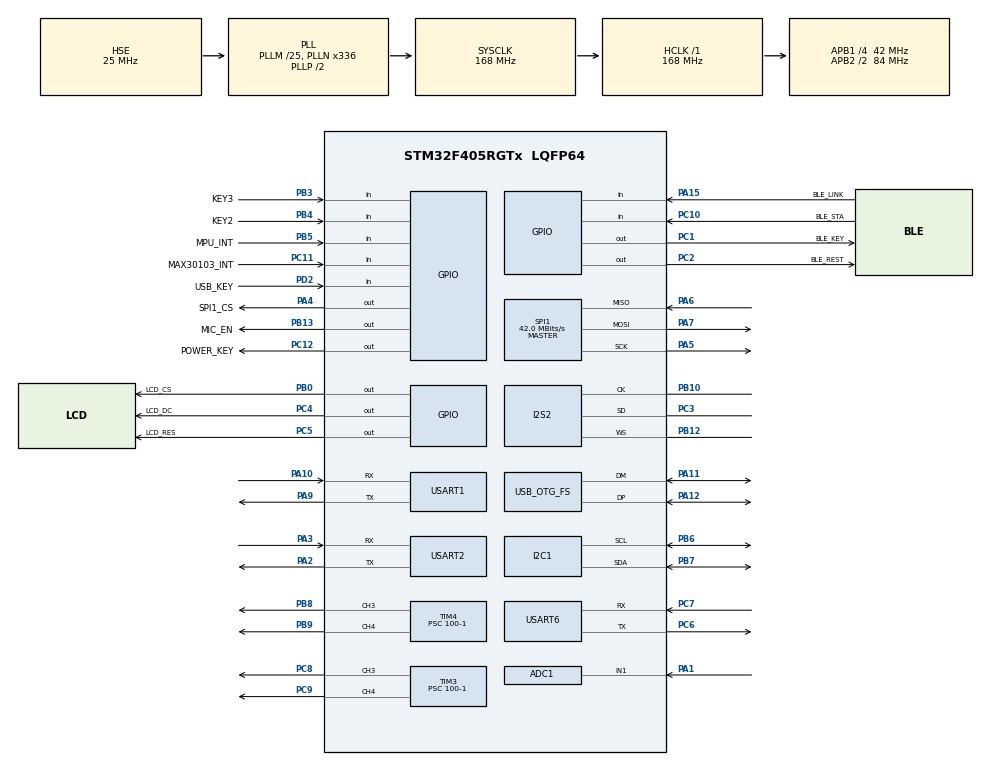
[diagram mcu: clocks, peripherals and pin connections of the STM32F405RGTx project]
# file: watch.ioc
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ADC1.Channel-0\#ChannelRegularConversion=ADC_CHANNEL_1
ADC1.NbrOfConversionFlag=1
ADC1.Rank-0\#ChannelRegularConversion=1
ADC1.SamplingTime-0\#ChannelRegularConversion=ADC_SAMPLETIME_3CYCLES
ADC1.master=1
Dma.Request0=SPI2_TX
Dma.Request1=USART2_TX
Dma.Request2=USART2_RX
Dma.Request3=SPI1_TX
Dma.Request4=USART1_RX
Dma.Request5=USART1_TX
Dma.SPI1_TX.3.Direction=DMA_MEMORY_TO_PERIPH
Dma.SPI1_TX.3.FIFOMode=DMA_FIFOMODE_DISABLE
Dma.SPI1_TX.3.Instance=DMA2_Stream3
Dma.SPI1_TX.3.MemDataAlignment=DMA_MDATAALIGN_BYTE
Dma.SPI1_TX.3.MemInc=DMA_MINC_ENABLE
Dma.SPI1_TX.3.Mode=DMA_NORMAL
Dma.SPI1_TX.3.PeriphDataAlignment=DMA_PDATAALIGN_BYTE
Dma.SPI1_TX.3.PeriphInc=DMA_PINC_DISABLE
Dma.SPI1_TX.3.Priority=DMA_PRIORITY_HIGH
Dma.SPI2_TX.0.Direction=DMA_MEMORY_TO_PERIPH
Dma.SPI2_TX.0.FIFOMode=DMA_FIFOMODE_DISABLE
Dma.SPI2_TX.0.Instance=DMA1_Stream4
Dma.SPI2_TX.0.MemDataAlignment=DMA_MDATAALIGN_BYTE
Dma.SPI2_TX.0.MemInc=DMA_MINC_ENABLE
Dma.SPI2_TX.0.Mode=DMA_NORMAL
Dma.SPI2_TX.0.PeriphDataAlignment=DMA_PDATAALIGN_BYTE
Dma.SPI2_TX.0.PeriphInc=DMA_PINC_DISABLE
Dma.SPI2_TX.0.Priority=DMA_PRIORITY_LOW
Dma.USART1_RX.4.Direction=DMA_PERIPH_TO_MEMORY
Dma.USART1_RX.4.FIFOMode=DMA_FIFOMODE_DISABLE
Dma.USART1_RX.4.Instance=DMA2_Stream2
Dma.USART1_RX.4.MemDataAlignment=DMA_MDATAALIGN_BYTE
Dma.USART1_RX.4.MemInc=DMA_MINC_ENABLE
Dma.USART1_RX.4.Mode=DMA_NORMAL
Dma.USART1_RX.4.PeriphDataAlignment=DMA_PDATAALIGN_BYTE
Dma.USART1_RX.4.PeriphInc=DMA_PINC_DISABLE
Dma.USART1_RX.4.Priority=DMA_PRIORITY_LOW
Dma.USART1_TX.5.Direction=DMA_MEMORY_TO_PERIPH
Dma.USART1_TX.5.FIFOMode=DMA_FIFOMODE_DISABLE
Dma.USART1_TX.5.Instance=DMA2_Stream7
Dma.USART1_TX.5.MemDataAlignment=DMA_MDATAALIGN_BYTE
Dma.USART1_TX.5.MemInc=DMA_MINC_ENABLE
Dma.USART1_TX.5.Mode=DMA_NORMAL
Dma.USART1_TX.5.PeriphDataAlignment=DMA_PDATAALIGN_BYTE
Dma.USART1_TX.5.PeriphInc=DMA_PINC_DISABLE
Dma.USART1_TX.5.Priority=DMA_PRIORITY_LOW
Dma.USART2_RX.2.Direction=DMA_PERIPH_TO_MEMORY
Dma.USART2_RX.2.FIFOMode=DMA_FIFOMODE_DISABLE
Dma.USART2_RX.2.Instance=DMA1_Stream5
Dma.USART2_RX.2.MemDataAlignment=DMA_MDATAALIGN_BYTE
Dma.USART2_RX.2.MemInc=DMA_MINC_ENABLE
Dma.USART2_RX.2.Mode=DMA_NORMAL
Dma.USART2_RX.2.PeriphDataAlignment=DMA_PDATAALIGN_BYTE
Dma.USART2_RX.2.PeriphInc=DMA_PINC_DISABLE
Dma.USART2_RX.2.Priority=DMA_PRIORITY_LOW
Dma.USART2_TX.1.Direction=DMA_MEMORY_TO_PERIPH
Dma.USART2_TX.1.FIFOMode=DMA_FIFOMODE_DISABLE
Dma.USART2_TX.1.Instance=DMA1_Stream6
Dma.USART2_TX.1.MemDataAlignment=DMA_MDATAALIGN_BYTE
Dma.USART2_TX.1.MemInc=DMA_MINC_ENABLE
Dma.USART2_TX.1.Mode=DMA_NORMAL
Dma.USART2_TX.1.PeriphDataAlignment=DMA_PDATAALIGN_BYTE
Dma.USART2_TX.1.PeriphInc=DMA_PINC_DISABLE
Dma.USART2_TX.1.Priority=DMA_PRIORITY_LOW
FATFS._CODE_PAGE=437
FATFS._MAX_SS=4096
FATFS._MIN_SS=4096
FATFS._USE_LFN=3
FREERTOS.Tasks01=main,0,1024,StartDefaultTask,Default,NULL,Dynamic,NULL,NULL;base,1,2048,StartTask02,Default,NULL,Dynamic,NULL,NULL;background,-1,128,StartTask03,Default,NULL,Dynamic,NULL,NULL
FREERTOS.configTOTAL_HEAP_SIZE=18432
I2S2.DataFormat=I2S_DATAFORMAT_24B
I2S2.ErrorAudioFreq=-0.36 %
I2S2.FullDuplexMode=I2S_FULLDUPLEXMODE_DISABLE
I2S2.Instance=SPI$Index
I2S2.RealAudioFreq=7.971 KHz
I2S2.VirtualMode=I2S_MODE_MASTER
Mcu.Family=STM32F4
Mcu.Name=STM32F405RGTx
Mcu.Package=LQFP64
NVIC.DMA1_Stream4_IRQn=true\:5\:0\:false\:false\:true\:true\:false\:true\:true
NVIC.DMA1_Stream5_IRQn=true\:5\:0\:false\:false\:true\:true\:false\:true\:true
NVIC.DMA1_Stream6_IRQn=true\:5\:0\:false\:false\:true\:true\:false\:true\:true
NVIC.DMA2_Stream2_IRQn=true\:5\:0\:false\:false\:true\:true\:false\:true\:true
NVIC.DMA2_Stream3_IRQn=true\:5\:0\:false\:false\:true\:true\:false\:true\:true
NVIC.DMA2_Stream7_IRQn=true\:5\:0\:false\:false\:true\:true\:false\:true\:true
NVIC.OTG_FS_IRQn=true\:5\:0\:false\:false\:true\:true\:false\:true\:true
NVIC.PriorityGroup=NVIC_PRIORITYGROUP_4
NVIC.TIM2_IRQn=true\:15\:0\:false\:false\:true\:false\:false\:true\:true
NVIC.TIM5_IRQn=true\:5\:0\:true\:false\:true\:true\:true\:true\:true
NVIC.TimeBase=TIM2_IRQn
NVIC.TimeBaseIP=TIM2
NVIC.USART1_IRQn=true\:5\:0\:false\:false\:true\:true\:true\:true\:true
NVIC.USART2_IRQn=true\:5\:0\:false\:false\:true\:true\:true\:true\:true
PA0-WKUP.GPIO_Label=KEY1
PA0-WKUP.Mode=SYS_WakeUp0
PA0-WKUP.Signal=SYS_WKUP
PA1.Signal=ADCx_IN1
PA10.Mode=Asynchronous
PA10.Signal=USART1_RX
PA11.Mode=Device_Only
PA11.Signal=USB_OTG_FS_DM
PA12.Mode=Device_Only
PA12.Signal=USB_OTG_FS_DP
PA13.Mode=Serial_Wire
PA13.Signal=SYS_JTMS-SWDIO
PA14.Mode=Serial_Wire
PA14.Signal=SYS_JTCK-SWCLK
PA15.GPIO_Label=BLE_LINK
PA15.Signal=GPIO_Input
PA2.Mode=Asynchronous
PA2.Signal=USART2_TX
PA3.Mode=Asynchronous
PA3.Signal=USART2_RX
PA4.GPIO_Label=SPI1_CS
PA4.GPIO_Speed=GPIO_SPEED_FREQ_VERY_HIGH
PA4.PinState=GPIO_PIN_SET
PA4.Signal=GPIO_Output
PA5.Mode=Full_Duplex_Master
PA5.Signal=SPI1_SCK
PA6.Mode=Full_Duplex_Master
PA6.Signal=SPI1_MISO
PA7.Mode=Full_Duplex_Master
PA7.Signal=SPI1_MOSI
PA9.Mode=Asynchronous
PA9.Signal=USART1_TX
PB0.GPIO_Label=LCD_CS
PB0.Signal=GPIO_Output
PB10.Mode=Half_Duplex_Master
PB10.Signal=I2S2_CK
PB12.Mode=Half_Duplex_Master
PB12.Signal=I2S2_WS
PB13.GPIO_Label=MIC_EN
PB13.Signal=GPIO_Output
PB3.GPIO_Label=KEY3
PB3.Signal=GPIO_Input
PB4.GPIO_Label=KEY2
PB4.Signal=GPIO_Input
PB5.GPIO_Label=MPU_INT
PB5.Signal=GPIO_Input
PB6.Mode=I2C
PB6.Signal=I2C1_SCL
PB7.Mode=I2C
PB7.Signal=I2C1_SDA
PB8.Signal=S_TIM4_CH3
PB9.Signal=S_TIM4_CH4
PC1.GPIO_Label=BLE_KEY
PC1.Signal=GPIO_Output
PC10.GPIO_Label=BLE_STA
PC10.Signal=GPIO_Input
PC11.GPIO_Label=MAX30103_INT
PC11.Signal=GPIO_Input
PC12.GPIO_Label=POWER_KEY
PC12.Signal=GPIO_Output
PC14-OSC32_IN.Mode=LSE-External-Oscillator
PC14-OSC32_IN.Signal=RCC_OSC32_IN
PC15-OSC32_OUT.Mode=LSE-External-Oscillator
PC15-OSC32_OUT.Signal=RCC_OSC32_OUT
PC2.GPIO_Label=BLE_REST
PC2.Signal=GPIO_Output
PC3.Mode=Half_Duplex_Master
PC3.Signal=I2S2_SD
PC4.GPIO_Label=LCD_DC
PC4.GPIO_PuPd=GPIO_NOPULL
PC4.GPIO_Speed=GPIO_SPEED_FREQ_HIGH
PC4.PinState=GPIO_PIN_RESET
PC4.Signal=GPIO_Output
PC5.GPIO_Label=LCD_RES
PC5.GPIO_PuPd=GPIO_PULLUP
PC5.PinState=GPIO_PIN_SET
PC5.Signal=GPIO_Output
PC6.Mode=Asynchronous
PC6.Signal=USART6_TX
PC7.Mode=Asynchronous
PC7.Signal=USART6_RX
PC8.Signal=S_TIM3_CH3
PC9.Signal=S_TIM3_CH4
PD2.GPIO_Label=USB_KEY
PD2.Signal=GPIO_Input
PH0-OSC_IN.Mode=HSE-External-Oscillator
PH0-OSC_IN.Signal=RCC_OSC_IN
PH1-OSC_OUT.Mode=HSE-External-Oscillator
PH1-OSC_OUT.Signal=RCC_OSC_OUT
ProjectManager.HeapSize=0x2500
ProjectManager.StackSize=0x2500
ProjectManager.TargetToolchain=MDK-ARM V5.32
RCC.48MHZClocksFreq_Value=48000000
RCC.AHBFreq_Value=168000000
RCC.APB1CLKDivider=RCC_HCLK_DIV4
RCC.APB1Freq_Value=42000000
RCC.APB1TimFreq_Value=84000000
RCC.APB2CLKDivider=RCC_HCLK_DIV2
RCC.APB2Freq_Value=84000000
RCC.APB2TimFreq_Value=168000000
RCC.CortexFreq_Value=168000000
RCC.HCLKFreq_Value=168000000
RCC.HSE_VALUE=25000000
RCC.HSI_VALUE=16000000
RCC.PLLI2SN=100
RCC.PLLM=25
RCC.PLLN=336
RCC.PLLQ=7
RCC.SYSCLKFreq_VALUE=168000000
RCC.SYSCLKSource=RCC_SYSCLKSOURCE_PLLCLK
RCC.VCOOutputFreq_Value=336000000
RTC.Format=RTC_FORMAT_BIN
SH.ADCx_IN1.0=ADC1_IN1,IN1
SH.S_TIM3_CH3.0=TIM3_CH3,PWM Generation3 CH3
SH.S_TIM3_CH4.0=TIM3_CH4,PWM Generation4 CH4
SH.S_TIM4_CH3.0=TIM4_CH3,PWM Generation3 CH3
SH.S_TIM4_CH4.0=TIM4_CH4,PWM Generation4 CH4
SPI1.BaudRatePrescaler=SPI_BAUDRATEPRESCALER_2
SPI1.CLKPhase=SPI_PHASE_2EDGE
SPI1.CLKPolarity=SPI_POLARITY_HIGH
SPI1.CalculateBaudRate=42.0 MBits/s
SPI1.Direction=SPI_DIRECTION_2LINES
SPI1.Mode=SPI_MODE_MASTER
SPI1.VirtualType=VM_MASTER
TIM3.Channel-PWM\ Generation3\ CH3=TIM_CHANNEL_3
TIM3.Channel-PWM\ Generation4\ CH4=TIM_CHANNEL_4
TIM3.Period=500-1
TIM3.Prescaler=100-1
TIM4.Channel-PWM\ Generation3\ CH3=TIM_CHANNEL_3
TIM4.Channel-PWM\ Generation4\ CH4=TIM_CHANNEL_4
TIM4.Period=500-1
TIM4.Prescaler=100-1
TIM5.Period=1000
TIM5.Prescaler=168
USART1.VirtualMode=VM_ASYNC
USART2.VirtualMode=VM_ASYNC
USART6.VirtualMode=VM_ASYNC
USB_DEVICE.CLASS_NAME_FS=HID
USB_DEVICE.VirtualMode-HID_FS=Hid
USB_DEVICE.VirtualModeFS=Hid_FS
USB_OTG_FS.VirtualMode=Device_Only
VP_FATFS_VS_Generic.Mode=User_defined
VP_FREERTOS_VS_CMSIS_V1.Mode=CMSIS_V1
VP_RTC_VS_RTC_Activate.Mode=RTC_Enabled
VP_RTC_VS_RTC_Calendar.Mode=RTC_Calendar
VP_SYS_VS_tim2.Mode=TIM2
VP_TIM5_VS_ClockSourceINT.Mode=Internal
VP_USB_DEVICE_VS_USB_DEVICE_HID_FS.Mode=HID_FS
board=custom

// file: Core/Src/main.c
/* USER CODE BEGIN Header */
/**
  ******************************************************************************
  * @file           : main.c
  * @brief          : Main program body
  ******************************************************************************
  * @attention
  *
  * Copyright (c) 2025 STMicroelectronics.
  * All rights reserved.
  *
  * This software is licensed under terms that can be found in the LICENSE file
  * in the root directory of this software component.
  * If no LICENSE file comes with this software, it is provided AS-IS.
  *
  ******************************************************************************
  */
/* USER CODE END Header */
#include "main.h"
#include "cmsis_os.h"
#include "adc.h"
#include "dma.h"
#include "fatfs.h"
#include "i2c.h"
#include "i2s.h"
#include "rtc.h"
#include "spi.h"
#include "tim.h"
#include "usart.h"
#include "usb_device.h"
#include "gpio.h"

/* USER CODE BEGIN Includes */
#include "driver_usart.h"
#include "app.h"
/* USER CODE END Includes */

void SystemClock_Config(void);
void MX_FREERTOS_Init(void);

int main(void)
{

  /* MCU Configuration--------------------------------------------------------*/

  /* Reset of all peripherals, Initializes the Flash interface and the Systick. */
  HAL_Init();

  /* Configure the system clock */
  SystemClock_Config();

  /* Initialize all configured peripherals */
  MX_GPIO_Init();
  MX_DMA_Init();
  MX_I2C1_Init();
  MX_I2S2_Init();
  MX_ADC1_Init();
  MX_RTC_Init();
  MX_SPI1_Init();
  MX_USART1_UART_Init();
  MX_USART2_UART_Init();
  MX_TIM4_Init();
  MX_TIM3_Init();
  MX_USART6_UART_Init();
  MX_FATFS_Init();
  MX_TIM5_Init();

  /* Call init function for freertos objects (in cmsis_os2.c) */
  MX_FREERTOS_Init();

  /* Start scheduler */
  osKernelStart();

  /* We should never get here as control is now taken by the scheduler */

  /* Infinite loop */
  while (1)
  {

  }
}

void SystemClock_Config(void)
{
  RCC_OscInitTypeDef RCC_OscInitStruct = {0};
  RCC_ClkInitTypeDef RCC_ClkInitStruct = {0};

  /** Configure the main internal regulator output voltage
  */
  __HAL_RCC_PWR_CLK_ENABLE();
  __HAL_PWR_VOLTAGESCALING_CONFIG(PWR_REGULATOR_VOLTAGE_SCALE1);

  /** Initializes the RCC Oscillators according to the specified parameters
  * in the RCC_OscInitTypeDef structure.
  */
  RCC_OscInitStruct.OscillatorType = RCC_OSCILLATORTYPE_LSI|RCC_OSCILLATORTYPE_HSE;
  RCC_OscInitStruct.HSEState = RCC_HSE_ON;
  RCC_OscInitStruct.LSIState = RCC_LSI_ON;
  RCC_OscInitStruct.PLL.PLLState = RCC_PLL_ON;
  RCC_OscInitStruct.PLL.PLLSource = RCC_PLLSOURCE_HSE;
  RCC_OscInitStruct.PLL.PLLM = 25;
  RCC_OscInitStruct.PLL.PLLN = 336;
  RCC_OscInitStruct.PLL.PLLP = RCC_PLLP_DIV2;
  RCC_OscInitStruct.PLL.PLLQ = 7;
  if (HAL_RCC_OscConfig(&RCC_OscInitStruct) != HAL_OK)
  {
    Error_Handler();
  }

  /** Initializes the CPU, AHB and APB buses clocks
  */
  RCC_ClkInitStruct.ClockType = RCC_CLOCKTYPE_HCLK|RCC_CLOCKTYPE_SYSCLK
                              |RCC_CLOCKTYPE_PCLK1|RCC_CLOCKTYPE_PCLK2;
  RCC_ClkInitStruct.SYSCLKSource = RCC_SYSCLKSOURCE_PLLCLK;
  RCC_ClkInitStruct.AHBCLKDivider = RCC_SYSCLK_DIV1;
  RCC_ClkInitStruct.APB1CLKDivider = RCC_HCLK_DIV4;
  RCC_ClkInitStruct.APB2CLKDivider = RCC_HCLK_DIV2;

  if (HAL_RCC_ClockConfig(&RCC_ClkInitStruct, FLASH_LATENCY_5) != HAL_OK)
  {
    Error_Handler();
  }
}

void HAL_TIM_PeriodElapsedCallback(TIM_HandleTypeDef *htim)
{
  if (htim->Instance == TIM2) {
    HAL_IncTick();
  }
}

void Error_Handler(void)
{
  __disable_irq();
  while (1)
  {
  }
}

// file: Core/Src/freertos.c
/* USER CODE BEGIN Header */
/**
  ******************************************************************************
  * File Name          : freertos.c
  * Description        : Code for freertos applications
  ******************************************************************************
  * @attention
  *
  * Copyright (c) 2025 STMicroelectronics.
  * All rights reserved.
  *
  * This software is licensed under terms that can be found in the LICENSE file
  * in the root directory of this software component.
  * If no LICENSE file comes with this software, it is provided AS-IS.
  *
  ******************************************************************************
  */
/* USER CODE END Header */

#include "FreeRTOS.h"
#include "task.h"
#include "main.h"
#include "cmsis_os.h"

/* USER CODE BEGIN Includes */
#include "app.h"
/* USER CODE END Includes */

osThreadId mainHandle;
osThreadId baseHandle;
osThreadId backgroundHandle;

void StartDefaultTask(void const * argument);
void StartTask02(void const * argument);
void StartTask03(void const * argument);

extern void MX_USB_DEVICE_Init(void);
void MX_FREERTOS_Init(void); /* (MISRA C 2004 rule 8.1) */

/* GetIdleTaskMemory prototype (linked to static allocation support) */
void vApplicationGetIdleTaskMemory( StaticTask_t **ppxIdleTaskTCBBuffer, StackType_t **ppxIdleTaskStackBuffer, uint32_t *pulIdleTaskStackSize );

/* USER CODE BEGIN GET_IDLE_TASK_MEMORY */
static StaticTask_t xIdleTaskTCBBuffer;
static StackType_t xIdleStack[configMINIMAL_STACK_SIZE];

void vApplicationGetIdleTaskMemory( StaticTask_t **ppxIdleTaskTCBBuffer, StackType_t **ppxIdleTaskStackBuffer, uint32_t *pulIdleTaskStackSize )
{
  *ppxIdleTaskTCBBuffer = &xIdleTaskTCBBuffer;
  *ppxIdleTaskStackBuffer = &xIdleStack[0];
  *pulIdleTaskStackSize = configMINIMAL_STACK_SIZE;
  /* place for user code */
}
/* USER CODE END GET_IDLE_TASK_MEMORY */

void MX_FREERTOS_Init(void) {

  /* Create the thread(s) */
  /* definition and creation of main */
  osThreadDef(main, StartDefaultTask, osPriorityNormal, 0, 1024);
  mainHandle = osThreadCreate(osThread(main), NULL);

  /* definition and creation of base */
  osThreadDef(base, StartTask02, osPriorityAboveNormal, 0, 2048);
  baseHandle = osThreadCreate(osThread(base), NULL);

  /* definition and creation of background */
  osThreadDef(background, StartTask03, osPriorityBelowNormal, 0, 128);
  backgroundHandle = osThreadCreate(osThread(background), NULL);

}

void StartDefaultTask(void const * argument)
{
  /* init code for USB_DEVICE */
  MX_USB_DEVICE_Init();
  /* USER CODE BEGIN StartDefaultTask */
  /* Infinite loop */
	app_watch_screen_task();
  for(;;)
  {
    osDelay(1);
  }
  /* USER CODE END StartDefaultTask */
}

void StartTask02(void const * argument)
{
  /* USER CODE BEGIN StartTask02 */
  /* Infinite loop */
	app_watch_base_task();
  for(;;)
  {
    osDelay(1);
  }
  /* USER CODE END StartTask02 */
}

void StartTask03(void const * argument)
{
  /* USER CODE BEGIN StartTask03 */
  /* Infinite loop */
  app_watch_background_task();
  for(;;)
  {
    osDelay(1);
  }
  /* USER CODE END StartTask03 */
}
